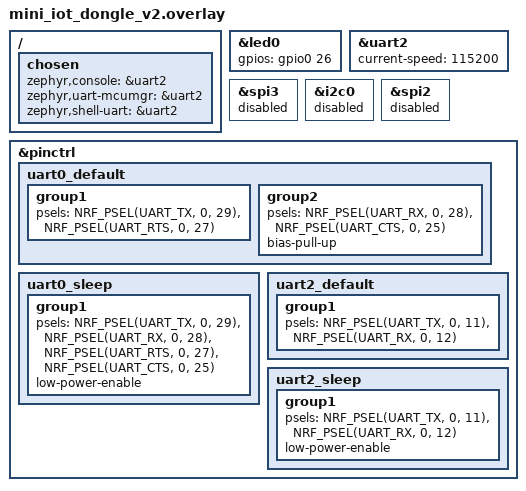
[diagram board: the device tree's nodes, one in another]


&led0 {
	gpios = <&gpio0 26 0>;
};

&uart2 {
	status = "okay";
	current-speed = <115200>;
};

arduino_spi: &spi3 {
	status = "disabled";
};

&i2c0 {
	status = "disabled";
};
&spi2 {
	status = "disabled";
};


&pinctrl {
	uart0_default: uart0_default {
		group1 {
			psels = <NRF_PSEL(UART_TX, 0, 29)>,
					<NRF_PSEL(UART_RTS, 0, 27)>;
		};
		group2 {
			psels = <NRF_PSEL(UART_RX, 0, 28)>,
					<NRF_PSEL(UART_CTS, 0, 25)>;
			bias-pull-up;
		};
	};

	uart0_sleep: uart0_sleep {
		group1 {
			psels = <NRF_PSEL(UART_TX, 0, 29)>,
			        <NRF_PSEL(UART_RX, 0, 28)>,
			        <NRF_PSEL(UART_RTS, 0, 27)>,
			        <NRF_PSEL(UART_CTS, 0, 25)>;
			low-power-enable;
		};
	};

	uart2_default: uart2_default {
		group1 {
			psels = <NRF_PSEL(UART_TX, 0, 11)>,
					<NRF_PSEL(UART_RX, 0, 12)>;
		};
	};

	uart2_sleep: uart2_sleep {
		group1 {
			psels = <NRF_PSEL(UART_TX, 0, 11)>,
					<NRF_PSEL(UART_RX, 0, 12)>;
			low-power-enable;
		};
	};
};

/ {
	chosen {
		zephyr,console = &uart2;
		zephyr,uart-mcumgr = &uart2;
		zephyr,shell-uart = &uart2;

	};
};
